# R9A02G021 register map
Vendor: Renesas Electronics Corporation; Series: RISC-V; File version: 1.10.00 + 202304131714_CPU
CPU: other r0p0, little endian, no MPU, no FPU, VTOR, 4 interrupt priority bits, 32 interrupts
Registers are 8-bit, read-write, reset 0x0 unless marked. A register's access mark holds for its fields unless they carry their own. Offsets are from the block's base; [hi:lo] are bit positions; {n}, {i} and the like mark numbered series.

## CPU_DBG — Debug Function
Base 0x4001B000
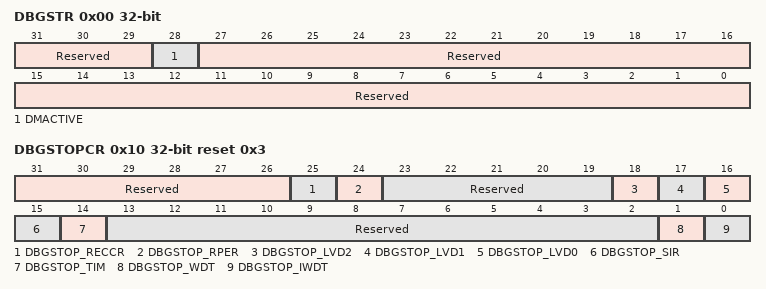
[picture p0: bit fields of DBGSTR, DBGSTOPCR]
0x00 DBGSTR 32-bit ro — Debug Status Register
  [31:29] Reserved — These bits are read as 000.
  [28] DMACTIVE — Debug active status from Debug Module
  [27:0] Reserved — These bits are read as 0000000000000000000000000000.
0x10 DBGSTOPCR 32-bit reset 0x3 — Debug Stop Control Register
  [31:26] Reserved — These bits are read as 000000. The write value should be 000000.
  [25] DBGSTOP_RECCR — Mask bit for RAM ECC error reset/interrupt
    0=Enable RAM ECC error reset/interrupt; 1=Mask RAM ECC error reset/interrupt
  [24] DBGSTOP_RPER — Mask bit for RAM parity error reset/interrupt
    0=Enable RAM parity error reset/interrupt; 1=Mask RAM parity error reset/interrupt
  [23:19] Reserved — These bits are read as 00000. The write value should be 00000.
  [18] DBGSTOP_LVD2 — Mask bit for LVD2 reset/interrpt
    0=Enable LVD2 reset/interrupt; 1=Mask LVD2 reset/interrupt
  [17] DBGSTOP_LVD1 — Mask bit for LVD1 reset/interrupt
    0=Enable LVD1 reset/interrupt; 1=Mask LVD1 reset/interrupt
  [16] DBGSTOP_LVD0 — Mask bit for LVD0 reset
    0=Enable LVD0 reset; 1=Mask LVD0 reset
  [15] DBGSTOP_SIR — Control bit for SAU and IICA operation in the OCD break mode
    0=Continue SAU and IICA operation; 1=Stop SAU and IICA operation
  [14] DBGSTOP_TIM — Control bit for RTC and TAU operation in the OCD break mode
    0=Continue RTC and TAU operation; 1=Stop RTC and TAU operation
  [13:2] Reserved — These bits are read as 000000000000. The write value should be 000000000000.
  [1] DBGSTOP_WDT — Mask bit for WDT reset/interrupt in the OCD run mode
    0=Enable WDT reset/interrupt; 1=Mask WDT reset/interrupt and stop WDT counter
  [0] DBGSTOP_IWDT — Mask bit for IWDT reset/interrupt in the OCD run mode
    0=Enable IWDT reset/interrupt; 1=Mask IWDT reset/interrupt and stop WDT counter
0xFD0 PIDR4 32-bit ro reset 0x4 — Peripheral Identification Register4
{0xFC0+4i} PIDR{i} 32-bit ro (i=5..7) — Peripheral Identification Register{i}
0xFE0 PIDR0 32-bit ro reset 0x5 — Peripheral Identification Register0
0xFE4 PIDR1 32-bit ro reset 0x30 — Peripheral Identification Register1
0xFE8 PIDR2 32-bit ro reset 0xAA — Peripheral Identification Register2
0xFEC PIDR3 32-bit ro — Peripheral Identification Register3
0xFF0 CIDR0 32-bit ro reset 0xD — Component Identification Register0
0xFF4 CIDR1 32-bit ro reset 0xF0 — Component Identification Register1
0xFF8 CIDR2 32-bit ro reset 0x5 — Component Identification Register2
0xFFC CIDR3 32-bit ro reset 0xB1 — Component Identification Register3

## CPU_AUX — CPU Auxiliary Register
Base 0x4001A000
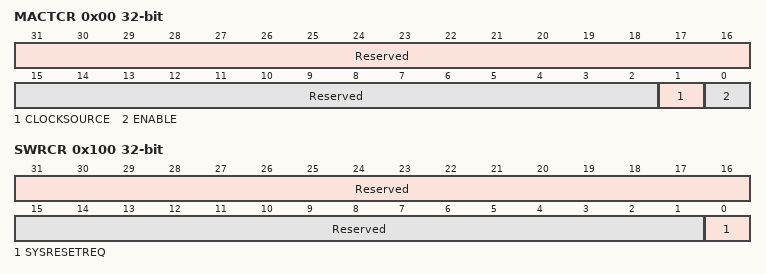
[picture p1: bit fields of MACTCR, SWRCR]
0x00 MACTCR 32-bit — Machine Timer Control Register
  [31:16] Reserved — These bits are read as 0000000000000000. The write value should be 0000000000000000.
  [15:2] Reserved — These bits are read as 00000000000000. The write value should be 00000000000000.
  [1] CLOCKSOURCE — Machine Timer clock source select
    0=Machine Timer Clock; 1=CPU Clock
  [0] ENABLE — Machine Timer clock enable
    0=No clock is supplied to Machine Timer; 1=Clock is supplied to Machine Timer
0x100 SWRCR 32-bit — Software Reset Control Register
  [31:16] Reserved — These bits are read as 0000000000000000. The write value should be 0000000000000000.
  [15:1] Reserved — These bits are read as 000000000000000. The write value should be 000000000000000.
  [0] SYSRESETREQ — System reset request
    0=Do not request a system reset; 1=Request a system reset
0x200 NMIADDR 32-bit — NMI Hander Address Register
  [31:0] NMIADDR — NMI handler address. Lower 6 bits must always be set 0.

## CLIC — Core-Local Interrupt Controller
Base 0xE2000000
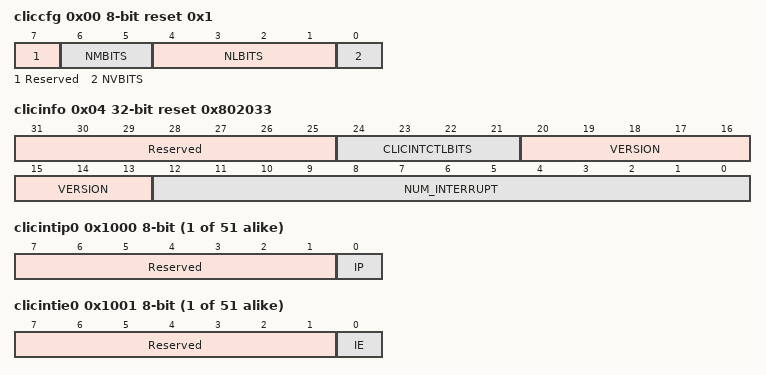
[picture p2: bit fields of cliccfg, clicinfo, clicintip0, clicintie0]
0x00 cliccfg reset 0x1 — CLIC Configuration Register
  [7] Reserved — This bit is read as 0. The write value should be 0.
  [6:5] NMBITS ro — Number of bits in clicintattr[i].MODE register
  [4:1] NLBITS — Number of bits in clicintctl[i] allocated for specifying interrupt levels.
  [0] NVBITS ro — Selective interrupt hardware vectoring feature is implemented. This bit is read as 1.
0x04 clicinfo 32-bit ro reset 0x802033 — CLIC Information Register
  [31:25] Reserved — These bits are read as 0000000.
  [24:21] CLICINTCTLBITS — The value of the CLICINTCTLBITS parameter
  [20:13] VERSION — Version of CLIC
  [12:0] NUM_INTERRUPT — Number of total interrupts supported by CLIC
{0x1000+4i} clicintip{i} (i=0..50) — CLIC Interrupt Pending Register
  [7:1] Reserved — These bits are read as 0000000. The write value should be 0000000.
  [0] IP — Pending bit for the associated interrupt
{0x1001+4i} clicintie{i} (i=0..50) — CLIC Interrupt Enable Register
  [7:1] Reserved — These bits are read as 0000000. The write value should be 0000000.
  [0] IE — Enable bit for the associated interrupt
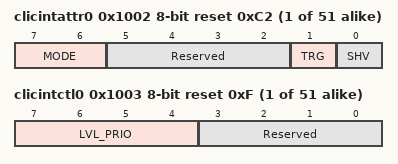
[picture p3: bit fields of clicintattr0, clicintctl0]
{0x1002+4i} clicintattr{i} (i=0..50) reset 0xC2
  [7:6] MODE ro — Privilege mode that the associated interrupt is triggered. Read value are 2'b11.
    3=Machine
  [5:2] Reserved — These bits are read as 0000. The write value should be 0000.
  [1] TRG ro — Trigger type for the associated interrupt. This bit is read as 1.
    1=Positive Edge
  [0] SHV — Selective Hardware Vectoring type for the associated interrupt
    0=Non-vectored; 1=Vector mode
{0x1003+4i} clicintctl{i} (i=0..50) reset 0xF
  [7:4] LVL_PRIO — Interrupt level and priority for the associated interrupt
  [3:0] Reserved — These bits are read as 1111. The write value should be 1111.

## MTIME — Machine Timer
Base 0xE6000000
0x00 mtime_lo 32-bit — Machine Timer Counter Register Low
0x04 mtime_hi 32-bit — Machine Timer Counter Register High
0x08 mtimecmp_lo 32-bit reset 0xFFFFFFFF — Machine Timer Comparator Register 0 Low
0x0C mtimecmp_hi 32-bit reset 0xFFFFFFFF — Machine Timer Comparator Register 0 High
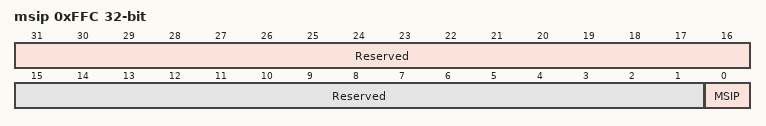
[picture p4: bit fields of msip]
0xFFC msip 32-bit — Triggering Software Interrupt
  [31:16] Reserved — These bits are read as 0000000000000000. The write value should be 0000000000000000.
  [15:1] Reserved — These bits are read as 000000000000000. The write value should be 000000000000000.
  [0] MSIP — Machine software interrupt control
    1=Generate a software interrupt; 0=Clear the pending software interrupt

## DBG — Debug Module
Base 0xE6800000
{0x80+4i} progbuf{i} (i=0..7) 32-bit — Program Buffer 0 to 7
{0xC0+4i} data{i} (i=0..3) 32-bit — Abstract Data 0 to 3
